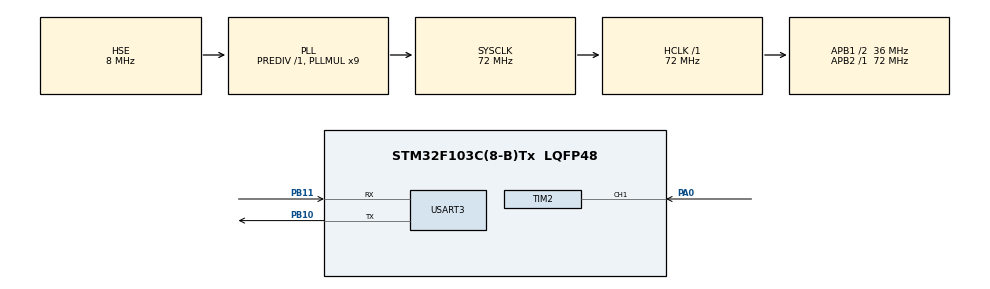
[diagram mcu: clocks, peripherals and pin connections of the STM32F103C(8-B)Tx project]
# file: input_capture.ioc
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Mcu.Family=STM32F1
Mcu.Name=STM32F103C(8-B)Tx
Mcu.Package=LQFP48
NVIC.PriorityGroup=NVIC_PRIORITYGROUP_4
NVIC.TIM2_IRQn=true\:0\:0\:false\:false\:true\:true\:true\:true
PA0-WKUP.GPIO_PuPd=GPIO_PULLDOWN
PA0-WKUP.Signal=S_TIM2_CH1_ETR
PB10.Mode=Asynchronous
PB10.Signal=USART3_TX
PB11.Mode=Asynchronous
PB11.Signal=USART3_RX
PD0-OSC_IN.Mode=HSE-External-Oscillator
PD0-OSC_IN.Signal=RCC_OSC_IN
PD1-OSC_OUT.Mode=HSE-External-Oscillator
PD1-OSC_OUT.Signal=RCC_OSC_OUT
ProjectManager.HeapSize=0x200
ProjectManager.StackSize=0x400
ProjectManager.TargetToolchain=STM32CubeIDE
RCC.AHBFreq_Value=72000000
RCC.APB1CLKDivider=RCC_HCLK_DIV2
RCC.APB1Freq_Value=36000000
RCC.APB1TimFreq_Value=72000000
RCC.APB2Freq_Value=72000000
RCC.APB2TimFreq_Value=72000000
RCC.HCLKFreq_Value=72000000
RCC.PLLMUL=RCC_PLL_MUL9
RCC.PLLSourceVirtual=RCC_PLLSOURCE_HSE
RCC.SYSCLKFreq_VALUE=72000000
RCC.SYSCLKSource=RCC_SYSCLKSOURCE_PLLCLK
RCC.USBFreq_Value=72000000
SH.S_TIM2_CH1_ETR.0=TIM2_CH1,Input_Capture1_from_TI1
TIM2.Channel-Input_Capture1_from_TI1=TIM_CHANNEL_1
TIM2.ClockDivision=TIM_CLOCKDIVISION_DIV1
TIM2.Prescaler=4*7200-1
USART3.VirtualMode=VM_ASYNC
VP_TIM2_VS_ClockSourceINT.Mode=Internal
board=custom

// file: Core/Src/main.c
/* USER CODE BEGIN Header */
/**
  ******************************************************************************
  * @file           : main.c
  * @brief          : Main program body
  ******************************************************************************
  * @attention
  *
  * Copyright (c) 2023 STMicroelectronics.
  * All rights reserved.
  *
  * This software is licensed under terms that can be found in the LICENSE file
  * in the root directory of this software component.
  * If no LICENSE file comes with this software, it is provided AS-IS.
  *
  ******************************************************************************
  */
/* USER CODE END Header */
#include "main.h"

/* USER CODE BEGIN Includes */
#include "math.h"
#include <stdio.h>
/* USER CODE END Includes */

/* USER CODE BEGIN PTD */
#define PUTCHAR_PROTOTYPE int __io_putchar(int ch)

/* USER CODE END PTD */

TIM_HandleTypeDef htim2;

UART_HandleTypeDef huart3;

void SystemClock_Config(void);
static void MX_GPIO_Init(void);
static void MX_TIM2_Init(void);
static void MX_USART3_UART_Init(void);

/* USER CODE BEGIN 0 */
#define TIMCLOCK   72000000
#define PRESCALAR  28800

uint32_t IC_Val1 = 0;
uint32_t IC_Val2 = 0;
uint32_t Difference = 0;
int Is_First_Captured = 0;
float frequency = 0;

void HAL_TIM_IC_CaptureCallback(TIM_HandleTypeDef *htim)
{
	if (htim->Channel == HAL_TIM_ACTIVE_CHANNEL_1)
		{
			if (Is_First_Captured==0) // if the first rising edge is not captured
			{
				IC_Val1 = HAL_TIM_ReadCapturedValue(htim, TIM_CHANNEL_1); // read the first value
				Is_First_Captured = 1;  // set the first captured as true
			}

			else   // If the first rising edge is captured, now we will capture the second edge
			{
				IC_Val2 = HAL_TIM_ReadCapturedValue(htim, TIM_CHANNEL_1);  // read second value

				if (IC_Val2 > IC_Val1)
				{
					Difference = IC_Val2-IC_Val1;
				}

				else if (IC_Val1 > IC_Val2)
				{
					Difference = (0xffffffff - IC_Val1) + IC_Val2;
				}

				float refClock = TIMCLOCK/(PRESCALAR);
				if(refClock/Difference < 0.1) frequency = 0;
				else	frequency = refClock/Difference;

				__HAL_TIM_SET_COUNTER(htim, 0);  // reset the counter
				Is_First_Captured = 0; // set it back to false
			}
		}

}

/* USER CODE END 0 */

int main(void)
{

  /* MCU Configuration--------------------------------------------------------*/

  /* Reset of all peripherals, Initializes the Flash interface and the Systick. */
  HAL_Init();

  /* Configure the system clock */
  SystemClock_Config();

  /* Initialize all configured peripherals */
  MX_GPIO_Init();
  MX_TIM2_Init();
  MX_USART3_UART_Init();
  /* USER CODE BEGIN 2 */
  HAL_TIM_IC_Start_IT(&htim2, TIM_CHANNEL_1);

  /* USER CODE END 2 */

  /* Infinite loop */
  while (1)
  {

    /* USER CODE BEGIN 3 */
	  printf("freq: %0.2f\n", frequency);

	  HAL_Delay(100);
  }
  /* USER CODE END 3 */
}

void SystemClock_Config(void)
{
  RCC_OscInitTypeDef RCC_OscInitStruct = {0};
  RCC_ClkInitTypeDef RCC_ClkInitStruct = {0};

  /** Initializes the RCC Oscillators according to the specified parameters
  * in the RCC_OscInitTypeDef structure.
  */
  RCC_OscInitStruct.OscillatorType = RCC_OSCILLATORTYPE_HSE;
  RCC_OscInitStruct.HSEState = RCC_HSE_ON;
  RCC_OscInitStruct.HSEPredivValue = RCC_HSE_PREDIV_DIV1;
  RCC_OscInitStruct.HSIState = RCC_HSI_ON;
  RCC_OscInitStruct.PLL.PLLState = RCC_PLL_ON;
  RCC_OscInitStruct.PLL.PLLSource = RCC_PLLSOURCE_HSE;
  RCC_OscInitStruct.PLL.PLLMUL = RCC_PLL_MUL9;
  if (HAL_RCC_OscConfig(&RCC_OscInitStruct) != HAL_OK)
  {
    Error_Handler();
  }

  /** Initializes the CPU, AHB and APB buses clocks
  */
  RCC_ClkInitStruct.ClockType = RCC_CLOCKTYPE_HCLK|RCC_CLOCKTYPE_SYSCLK
                              |RCC_CLOCKTYPE_PCLK1|RCC_CLOCKTYPE_PCLK2;
  RCC_ClkInitStruct.SYSCLKSource = RCC_SYSCLKSOURCE_PLLCLK;
  RCC_ClkInitStruct.AHBCLKDivider = RCC_SYSCLK_DIV1;
  RCC_ClkInitStruct.APB1CLKDivider = RCC_HCLK_DIV2;
  RCC_ClkInitStruct.APB2CLKDivider = RCC_HCLK_DIV1;

  if (HAL_RCC_ClockConfig(&RCC_ClkInitStruct, FLASH_LATENCY_2) != HAL_OK)
  {
    Error_Handler();
  }
}

static void MX_TIM2_Init(void)
{

  TIM_ClockConfigTypeDef sClockSourceConfig = {0};
  TIM_MasterConfigTypeDef sMasterConfig = {0};
  TIM_IC_InitTypeDef sConfigIC = {0};

  htim2.Instance = TIM2;
  htim2.Init.Prescaler = 4*7200-1;
  htim2.Init.CounterMode = TIM_COUNTERMODE_UP;
  htim2.Init.Period = 65535;
  htim2.Init.ClockDivision = TIM_CLOCKDIVISION_DIV1;
  htim2.Init.AutoReloadPreload = TIM_AUTORELOAD_PRELOAD_DISABLE;
  if (HAL_TIM_Base_Init(&htim2) != HAL_OK)
  {
    Error_Handler();
  }
  sClockSourceConfig.ClockSource = TIM_CLOCKSOURCE_INTERNAL;
  if (HAL_TIM_ConfigClockSource(&htim2, &sClockSourceConfig) != HAL_OK)
  {
    Error_Handler();
  }
  if (HAL_TIM_IC_Init(&htim2) != HAL_OK)
  {
    Error_Handler();
  }
  sMasterConfig.MasterOutputTrigger = TIM_TRGO_RESET;
  sMasterConfig.MasterSlaveMode = TIM_MASTERSLAVEMODE_DISABLE;
  if (HAL_TIMEx_MasterConfigSynchronization(&htim2, &sMasterConfig) != HAL_OK)
  {
    Error_Handler();
  }
  sConfigIC.ICPolarity = TIM_INPUTCHANNELPOLARITY_RISING;
  sConfigIC.ICSelection = TIM_ICSELECTION_DIRECTTI;
  sConfigIC.ICPrescaler = TIM_ICPSC_DIV1;
  sConfigIC.ICFilter = 0;
  if (HAL_TIM_IC_ConfigChannel(&htim2, &sConfigIC, TIM_CHANNEL_1) != HAL_OK)
  {
    Error_Handler();
  }

}

static void MX_USART3_UART_Init(void)
{

  huart3.Instance = USART3;
  huart3.Init.BaudRate = 115200;
  huart3.Init.WordLength = UART_WORDLENGTH_8B;
  huart3.Init.StopBits = UART_STOPBITS_1;
  huart3.Init.Parity = UART_PARITY_NONE;
  huart3.Init.Mode = UART_MODE_TX_RX;
  huart3.Init.HwFlowCtl = UART_HWCONTROL_NONE;
  huart3.Init.OverSampling = UART_OVERSAMPLING_16;
  if (HAL_UART_Init(&huart3) != HAL_OK)
  {
    Error_Handler();
  }

}

static void MX_GPIO_Init(void)
{

  /* GPIO Ports Clock Enable */
  __HAL_RCC_GPIOD_CLK_ENABLE();
  __HAL_RCC_GPIOA_CLK_ENABLE();
  __HAL_RCC_GPIOB_CLK_ENABLE();

}

/* USER CODE BEGIN 4 */
PUTCHAR_PROTOTYPE
{
  /* Place your implementation of fputc here */
  /* e.g. write a character to the USART1 and Loop until the end of transmission */
  HAL_UART_Transmit(&huart3, (uint8_t *)&ch, 1, 0xFFFF);

  return ch;
}
/* USER CODE END 4 */

void Error_Handler(void)
{
  __disable_irq();
  while (1)
  {
  }
}
